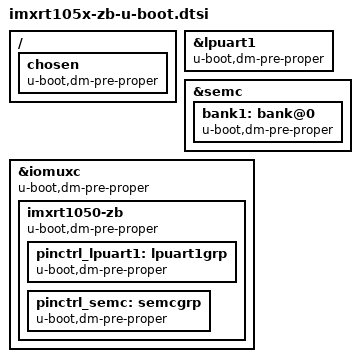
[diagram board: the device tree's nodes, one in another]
// SPDX-License-Identifier: (GPL-2.0+ OR BSD-3-Clause)
/*
 * Copyright (C) 2020
 * Author(s): Sicris Rey Embay <sicris.embay@gmail.com>
 */

/ {
	chosen {
        u-boot,dm-pre-proper;
	};
};

&lpuart1 { /* console */
    u-boot,dm-pre-proper;
};

&semc {
	bank1: bank@0 {
        u-boot,dm-pre-proper;
	};
};

&iomuxc {
    u-boot,dm-pre-proper;
    
	imxrt1050-zb {
        u-boot,dm-pre-proper;
        
		pinctrl_lpuart1: lpuart1grp {
            u-boot,dm-pre-proper;
		};

		pinctrl_semc: semcgrp {
            u-boot,dm-pre-proper;
		};
	};
};
